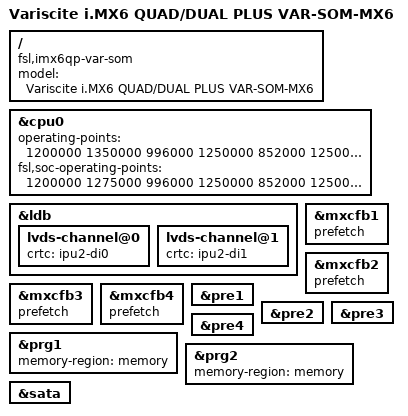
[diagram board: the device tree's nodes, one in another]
/*
 * Copyright (C) 2015-2017 Variscite Ltd.
 *
 * This program is free software; you can redistribute it and/or modify
 * it under the terms of the GNU General Public License version 2 as
 * published by the Free Software Foundation.
 */

/dts-v1/;

#include "imx6qp.dtsi"
#include "imx6qdl-var-som.dtsi"

/ {
	model = "Variscite i.MX6 QUAD/DUAL PLUS VAR-SOM-MX6";
	compatible = "fsl,imx6qp-var-som", "fsl,imx6qp";
};

&cpu0 {
	operating-points = <
		/* kHz    uV */
		1200000	1350000
		996000	1250000
		852000	1250000
		792000	1175000
		396000	1175000
	>;

	fsl,soc-operating-points = <
		/* ARM kHz  SOC-PU uV */
		1200000	1275000
		996000	1250000
		852000	1250000
		792000	1250000
		396000	1250000
	>;
};

&ldb {
	lvds-channel@0 {
		crtc = "ipu2-di0";
	};

	lvds-channel@1 {
		crtc = "ipu2-di1";
	};
};

&mxcfb1 {
	prefetch;
	status = "okay";
};

&mxcfb2 {
	prefetch;
	status = "okay";
};

&mxcfb3 {
	prefetch;
	status = "okay";
};

&mxcfb4 {
	prefetch;
	status = "okay";
};

&pre1 {
	status = "okay";
};

&pre2 {
	status = "okay";
};

&pre3 {
	status = "okay";
};

&pre4 {
	status = "okay";
};

&prg1 {
	memory-region = <&memory>;
	status = "okay";
};

&prg2 {
	memory-region = <&memory>;
	status = "okay";
};

&sata {
	status = "okay";
};
